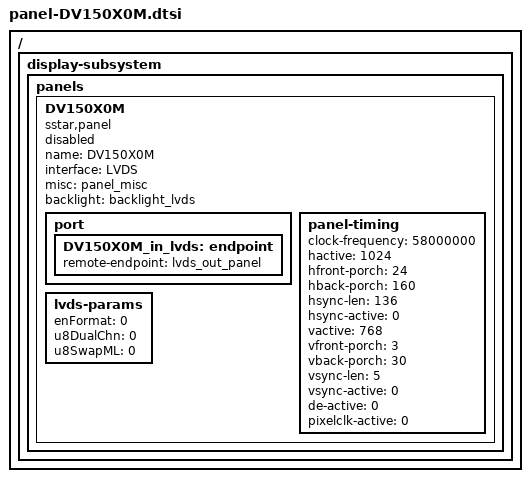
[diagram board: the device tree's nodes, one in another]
/*
* DV150X0M-panel.dtsi- Sigmastar
*
* Copyright (c) [2019~2020] SigmaStar Technology.
*
*
* This software is licensed under the terms of the GNU General Public
* License version 2, as published by the Free Software Foundation, and
* may be copied, distributed, and modified under those terms.
*
* This program is distributed in the hope that it will be useful,
* but WITHOUT ANY WARRANTY; without even the implied warranty of
* MERCHANTABILITY or FITNESS FOR A PARTICULAR PURPOSE.  See the
* GNU General Public License version 2 for more details.
*
*/

/ {
    display-subsystem {
        panels {
            DV150X0M {
                compatible = "sstar,panel";
                name = "DV150X0M";
                interface = "LVDS"; /* TTL/MIPI/LVDS/BT1120/BT656 */
                misc = <&panel_misc>;
                backlight = <&backlight_lvds>;
                status = "disable";

                port {
                    DV150X0M_in_lvds: endpoint {
                        remote-endpoint = <&lvds_out_panel>;
                    };
                };

                panel-timing {
                    clock-frequency = <58000000>;
                    hactive = <1024>;
                    hfront-porch = <24>;
                    hback-porch = <160>;
                    hsync-len = <136>;
                    hsync-active = <0>;
                    vactive = <768>;
                    vfront-porch = <3>;
                    vback-porch = <30>;
                    vsync-len = <5>;
                    vsync-active = <0>;
                    de-active = <0>;
                    pixelclk-active = <0>;
                };
                lvds-params {
                    enFormat = <0>;
                    u8DualChn = <0>;
                    u8SwapML = <0>;
                };
            };
        };
    };
};
